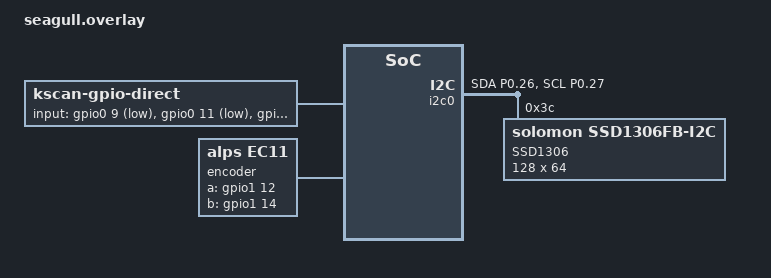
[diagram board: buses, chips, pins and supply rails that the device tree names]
/ {
    chosen {
        zephyr,display = &oled;
        zmk,kscan = &kscan0;
    };

    kscan0: kscan {
        compatible = "zmk,kscan-gpio-direct";
        label = "KSCAN";
        input-gpios =
            <&gpio0 9  (GPIO_ACTIVE_LOW | GPIO_PULL_UP)>,
            <&gpio0 11 (GPIO_ACTIVE_LOW | GPIO_PULL_UP)>,
            <&gpio0 10 (GPIO_ACTIVE_LOW | GPIO_PULL_UP)>,
            <&gpio1 13 (GPIO_ACTIVE_LOW | GPIO_PULL_UP)>,
            <&gpio0 30 (GPIO_ACTIVE_LOW | GPIO_PULL_UP)>,
            <&gpio0 31 (GPIO_ACTIVE_LOW | GPIO_PULL_UP)>,
            <&gpio1 11 (GPIO_ACTIVE_LOW | GPIO_PULL_UP)>,
            <&gpio1 15 (GPIO_ACTIVE_LOW | GPIO_PULL_UP)>,
            <&gpio1 10 (GPIO_ACTIVE_LOW | GPIO_PULL_UP)>,
            <&gpio0 12 (GPIO_ACTIVE_LOW | GPIO_PULL_UP)>,
            <&gpio1 8  (GPIO_ACTIVE_LOW | GPIO_PULL_UP)>,
            <&gpio0 3  (GPIO_ACTIVE_LOW | GPIO_PULL_UP)>,
            <&gpio0 19 (GPIO_ACTIVE_LOW | GPIO_PULL_UP)>,
            <&gpio1 3  (GPIO_ACTIVE_LOW | GPIO_PULL_UP)>,
            <&gpio1 4  (GPIO_ACTIVE_LOW | GPIO_PULL_UP)>,
            <&gpio0 17 (GPIO_ACTIVE_LOW | GPIO_PULL_UP)>,
            <&gpio0 5  (GPIO_ACTIVE_LOW | GPIO_PULL_UP)>,
            <&gpio1 1  (GPIO_ACTIVE_LOW | GPIO_PULL_UP)>,
            <&gpio1 0  (GPIO_ACTIVE_LOW | GPIO_PULL_UP)>,
            <&gpio0 21 (GPIO_ACTIVE_LOW | GPIO_PULL_UP)>,
            <&gpio1 5  (GPIO_ACTIVE_LOW | GPIO_PULL_UP)>,
            <&gpio1 6  (GPIO_ACTIVE_LOW | GPIO_PULL_UP)>,
            <&gpio0 22 (GPIO_ACTIVE_LOW | GPIO_PULL_UP)>,
            <&gpio0 23 (GPIO_ACTIVE_LOW | GPIO_PULL_UP)>;
    };

    encoder: encoder {
        compatible = "alps,ec11";
        a-gpios = <&gpio1 12 (GPIO_ACTIVE_HIGH | GPIO_PULL_UP)>;
        b-gpios = <&gpio1 14 (GPIO_ACTIVE_HIGH | GPIO_PULL_UP)>;
        steps = <24>;
        status = "okay";
    };

    sensors: sensors {
        compatible = "zmk,keymap-sensors";
        sensors = <&encoder>;
        triggers-per-rotation = <12>;
    };
};

&i2c0 {
    status = "okay";

    pinctrl-0 = <&i2c0_default>;
    pinctrl-1 = <&i2c0_sleep>;
    pinctrl-names = "default", "sleep";

    oled: ssd1306@3c {
        compatible = "solomon,ssd1306fb-i2c";
        reg = <0x3c>;
        width = <128>;
        height = <64>;
        label = "SSD1306";
    };
};

&pinctrl {
    i2c0_default: i2c0_default {
        group1 {
            psels = <NRF_PSEL(TWIM_SDA, 0, 26) NRF_PSEL(TWIM_SCL, 0, 27)>;
        };
    };

    i2c0_sleep: i2c0_sleep {
        group1 {
            psels = <NRF_PSEL(TWIM_SDA, 0, 26) NRF_PSEL(TWIM_SCL, 0, 27)>;
            low-power-enable;
        };
    };
};
